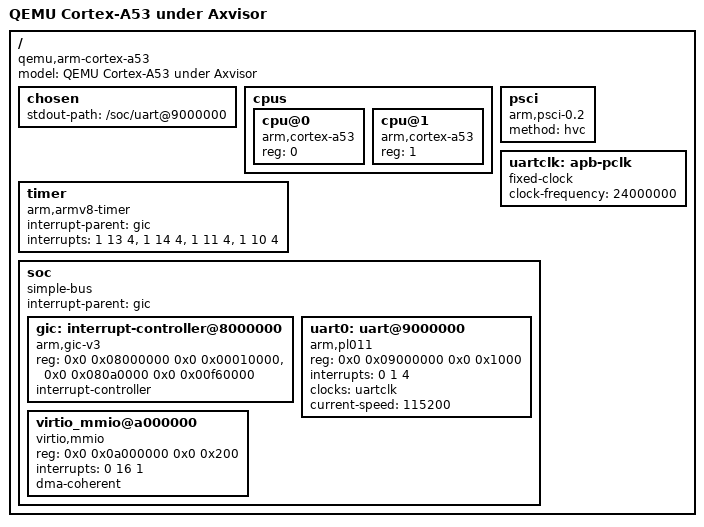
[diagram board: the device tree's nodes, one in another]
/*
 * Reference devicetree for the FreeRTOS VTP guest.
 *
 * The guest DTB used at runtime is GENERATED by Axvisor (the VM config has no
 * dtb_path). For a `virtualized` guest with a virtio-net virtual device, the
 * generated DTB contains the nodes below. This file documents the guest-visible
 * platform for integrators who build FreeRTOS with a compiled-in devicetree,
 * so that addresses/IRQs match Axvisor's machine profile and the virtio-net
 * fixed binding.
 */

/dts-v1/;

/ {
	#address-cells = <2>;
	#size-cells = <2>;
	model = "QEMU Cortex-A53 under Axvisor";
	compatible = "qemu,arm-cortex-a53";

	chosen {
		stdout-path = "/soc/uart@9000000";
	};

	cpus {
		#address-cells = <1>;
		#size-cells = <0>;

		cpu@0 {
			device_type = "cpu";
			compatible = "arm,cortex-a53";
			reg = <0>;
		};

		cpu@1 {
			device_type = "cpu";
			compatible = "arm,cortex-a53";
			reg = <1>;
		};
	};

	psci {
		compatible = "arm,psci-0.2";
		method = "hvc";
	};

	timer {
		compatible = "arm,armv8-timer";
		interrupt-parent = <&gic>;
		interrupts = <1 13 4>,
			     <1 14 4>,
			     <1 11 4>,
			     <1 10 4>;
	};

	uartclk: apb-pclk {
		compatible = "fixed-clock";
		clock-frequency = <24000000>;
		#clock-cells = <0>;
	};

	soc {
		#address-cells = <2>;
		#size-cells = <2>;
		compatible = "simple-bus";
		ranges;
		interrupt-parent = <&gic>;

		gic: interrupt-controller@8000000 {
			compatible = "arm,gic-v3", "arm,gic";
			reg = <0x0 0x08000000 0x0 0x00010000>,
			      <0x0 0x080a0000 0x0 0x00f60000>;
			interrupt-controller;
			#interrupt-cells = <3>;
			#address-cells = <2>;
			#size-cells = <2>;
			status = "okay";
		};

		uart0: uart@9000000 {
			compatible = "arm,pl011", "arm,primecell";
			reg = <0x0 0x09000000 0x0 0x1000>;
			interrupts = <0 1 4>; /* SPI 33 */
			clocks = <&uartclk>;
			current-speed = <115200>;
			status = "okay";
		};

		/*
		 * Axvisor-generated virtio-net device (fixed binding):
		 * MMIO 0x0a00_0000/0x200, SPI 48, level, dma-coherent.
		 */
		virtio_mmio@a000000 {
			compatible = "virtio,mmio";
			reg = <0x0 0x0a000000 0x0 0x200>;
			interrupts = <0 16 1>; /* SPI 48 */
			dma-coherent;
			status = "okay";
		};
	};
};
